# WKUP_SEC_MMR_WKUP_SEC_MMR_CFG0_45A20000h register map
Vendor: Texas Instruments
Peripheral module from a debugger description file (folder AM275x).
Registers are 32-bit, read-only, reset 0x0 unless marked. A register's access mark holds for its fields unless they carry their own. Offsets are as the file gives them; lines under a group give offsets from that group; [hi:lo] are bit positions; {n}, {i} and the like mark numbered series; 'fields as' and 'values as' point back to an identical list; <NAME> marks a mode.

## WKUP_SEC_MMR_CFG0
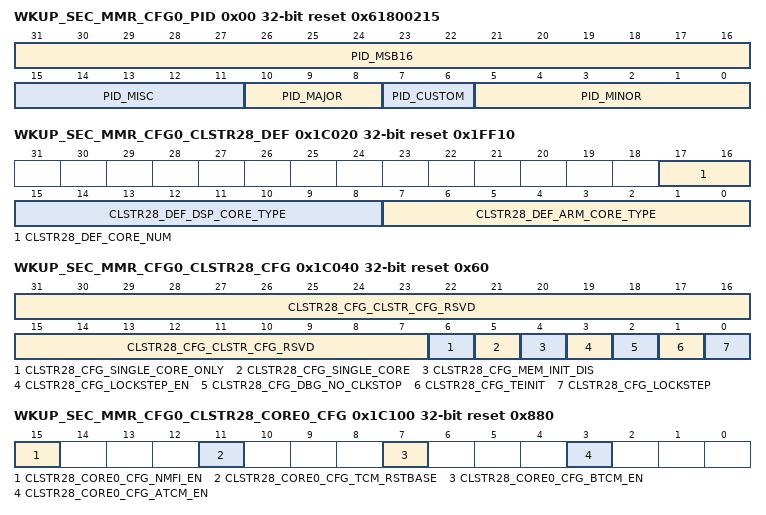
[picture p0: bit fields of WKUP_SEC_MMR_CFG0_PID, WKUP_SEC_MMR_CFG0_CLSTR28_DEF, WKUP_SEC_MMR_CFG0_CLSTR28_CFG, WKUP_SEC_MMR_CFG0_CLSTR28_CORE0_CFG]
0x00 WKUP_SEC_MMR_CFG0_PID reset 0x61800215
  [31:16] PID_MSB16 — Reset Source: mod_g_rst_n
  [15:11] PID_MISC — Reset Source: mod_g_rst_n
  [10:8] PID_MAJOR — Reset Source: mod_g_rst_n
  [7:6] PID_CUSTOM — Reset Source: mod_g_rst_n
  [5:0] PID_MINOR — Reset Source: mod_g_rst_n
0x1C020 WKUP_SEC_MMR_CFG0_CLSTR28_DEF reset 0x1FF10 — Defines the type of the processor cluster
  [17:16] CLSTR28_DEF_CORE_NUM — Number of cores in cluster 001 - Single Core 010 - Dual Core Reset Source: mod_g_rst_n
  [15:8] CLSTR28_DEF_DSP_CORE_TYPE — DSP core type configurationField values (others are reserved):8'h00 - C7x8'h01 - C6x8'hFF - Not DSP Reset Source: mod_g_rst_n
  [7:0] CLSTR28_DEF_ARM_CORE_TYPE — ARM core type configurationField values (others are reserved):8'h00 - A538'h01 - A578'h10 - R58'h11 - M4F8'hFF - Not ARM Reset Source: mod_g_rst_n
0x1C040 WKUP_SEC_MMR_CFG0_CLSTR28_CFG access per field reset 0x60 — Configures cluster level characteristics
  [31:7] CLSTR28_CFG_CLSTR_CFG_RSVD rw — Reserved for future use. Write '0' to ensure compatibility with future devices. Reset Source: sys_por_rst_n
  [6] CLSTR28_CFG_SINGLE_CORE_ONLY ro — Single / Dual CPU Mode Supported: 0 = Both Dual and Single Core are supported 1 = Only Single Core Mode is Supported Reset Source: sys_por_rst_n
  [5] CLSTR28_CFG_SINGLE_CORE ro — Single / Dual CPU Mode: 0 = Unsupported on this device 1 = Only CPU0 is active. Reset Source: sys_por_rst_n
  [4] CLSTR28_CFG_MEM_INIT_DIS rw — Disables SRAM initialization (TCM, Cache Tags, etc) at resetInitialization must be performed for proper initial ECC initialization. The mem_init_dis value must be selected prior to R5 reset assertion. 1'b0 - Perform memory initialization 1'b1 - Disable memory initialization Reset Source: mod_g_rst_n
  [3] CLSTR28_CFG_LOCKSTEP_EN ro — Lockstep Not Supported Reset Source: sys_por_rst_n
  [2] CLSTR28_CFG_DBG_NO_CLKSTOP rw — CPU clockstop behavior 0 - CPU clocks stopped and nCLOCKSTOPPED asserted in standby mode 1 - CPU clocks not stopped in standby mode Reset Source: sys_por_rst_n
  [1] CLSTR28_CFG_TEINIT rw — Exception handling state at reset:0 - ARM mode1 - Thumb modeCAUTION: This bit must not be modified if R5F core has been released from reset. Reset Source: sys_por_rst_n
  [0] CLSTR28_CFG_LOCKSTEP ro — Lockstep Not Supported Reset Source: sys_por_rst_n
0x1C080 WKUP_SEC_MMR_CFG0_CLSTR28_PMCTRL — Configures Cluster overall power state
  [31:0] CLSTR28_PMCTRL_RESERVED — Not used for Device Manager R5F
0x1C090 WKUP_SEC_MMR_CFG0_CLSTR28_PMSTAT — Shows Cluster overall power status
  [31:0] CLSTR28_PMSTAT_RESERVED — Not used for Device Manager R5F
0x1C100 WKUP_SEC_MMR_CFG0_CLSTR28_CORE0_CFG rw reset 0x880 — Configures the TCM and interrupt operation of R5 Core0
  [15] CLSTR28_CORE0_CFG_NMFI_EN — Enable Core0 Non-Maskable Fast InterruptsCAUTION: This bit must not be modified if R5F core has been released from reset. Reset Source: sys_por_rst_n
  [11] CLSTR28_CORE0_CFG_TCM_RSTBASE — Core0 A/BTCM Reset Base Address Indicator 0 - BTCM located at address 0x0 1 - ATCM located at address 0x0CAUTION: This bit must not be modified if R5F core has been released from reset. Reset Source: sys_por_rst_n
  [7] CLSTR28_CORE0_CFG_BTCM_EN — Enable Core0 BTCM RAM at resetCAUTION: This bit must not be modified if R5F core has been released from reset. Reset Source: sys_por_rst_n
  [3] CLSTR28_CORE0_CFG_ATCM_EN — Enable Core0 ATCM RAM at resetCAUTION: This bit must not be modified if R5F core has been released from reset. Reset Source: sys_por_rst_n
0x1C110 WKUP_SEC_MMR_CFG0_CLSTR28_CORE0_BOOTVECT_LO rw reset 0x200 — Contains the lower 32 bits of the boot vector location for R5 Core0. Bits 4:0 are not used and are always 0.
  [31:7] CLSTR28_CORE0_BOOTVECT_LO_VECT_ADDR — Specifies the lower 25 bits of the 41-bit vector address corresponding to Vector Table address bits[31:7]. Note bits 6:0 of the Vector Table address are always 0. Reset Source: sys_por_rst_n
0x1C114 WKUP_SEC_MMR_CFG0_CLSTR28_CORE0_BOOTVECT_HI rw — Contains the lower 16 bits of the boot vector location for R5 Core0
  [15:0] CLSTR28_CORE0_BOOTVECT_HI_VECT_ADDR — Specifies the upper 16 bits of the 41-bit vector address corresponding to Vector Table address bits[47:32]. Reset Source: sys_por_rst_n
0x1C120 WKUP_SEC_MMR_CFG0_CLSTR28_CORE0_PMCTRL rw — Configures Cluster Core0 power state
  [0] CLSTR28_CORE0_PMCTRL_CORE_HALT — Halt Core0Field values (others are reserved):1'b0 - CPU is held waiting to begin execution after reset is released1'b1 - CPU is released to execute Reset Source: sys_por_rst_n
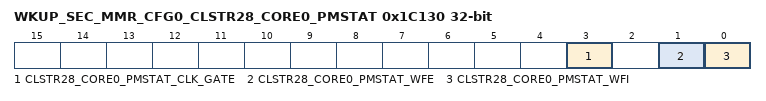
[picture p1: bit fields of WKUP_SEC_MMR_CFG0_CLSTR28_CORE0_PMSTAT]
0x1C130 WKUP_SEC_MMR_CFG0_CLSTR28_CORE0_PMSTAT — Shows Cluster Core0 power status
  [3] CLSTR28_CORE0_PMSTAT_CLK_GATE — Core0 Clocked stopped due to WFI or WFE stateNote: Bit value is invalid when Core0 is in reset Reset Source: mod_g_rst_n
  [1] CLSTR28_CORE0_PMSTAT_WFE — Core0 WFEWhen 0, indicates that Core0 is in the WFE stateNote: Bit value is invalid when Core0 is in reset Reset Source: mod_g_rst_n
  [0] CLSTR28_CORE0_PMSTAT_WFI — Core0 WFIWhen 0, indicates that Core0 is in the WFI stateNote: Bit value is invalid when Core0 is in reset Reset Source: mod_g_rst_n
